# STM32C531xx register map
File version: 1.0
Registers are 32-bit, read-write, reset 0x0 unless marked. A register's access mark holds for its fields unless they carry their own. Offsets are from the block's base; [hi:lo] are bit positions; {n}, {i} and the like mark numbered series.

## PWR — Power Control (PWR)
Base 0x44020800
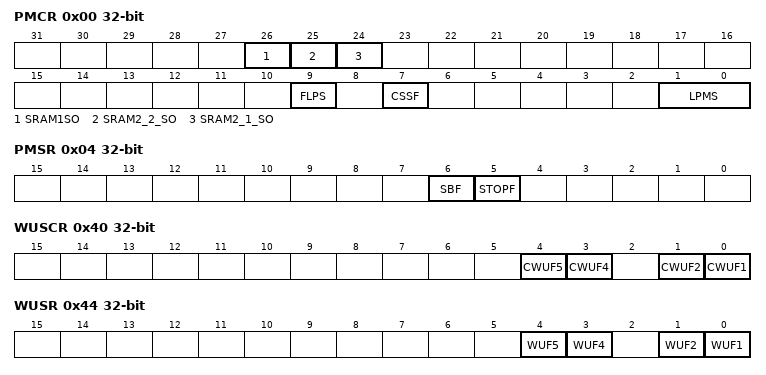
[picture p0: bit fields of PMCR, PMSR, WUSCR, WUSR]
0x00 PMCR — PWR power mode control register
  [26] SRAM1SO
  [25] SRAM2_2_SO
  [24] SRAM2_1_SO
  [9] FLPS
  [7] CSSF
  [1:0] LPMS — low-power mode selection
0x04 PMSR ro — PWR status register
  [6] SBF — System standby flag
  [5] STOPF — Stop flag
0x24 RTCCR — PWR RTC domain control register
  [0] DRTCP — Disable RTC domain write protection
0x34 VMCR — PWR voltage monitor control register
  [0] PVDE — PVD enable
0x3C VMSR ro — PWR voltage monitor status register
  [22] PVDO — programmable voltage detect output
0x40 WUSCR — PWR wake-up status clear register
  [4] CWUF5, [3] CWUF4, [1] CWUF2, [0] CWUF1
0x44 WUSR ro — PWR wake-up status register
  [4] WUF5 — wake-up pin WUFx flag
  [3] WUF4 — wake-up pin WUFx flag
  [1] WUF2 — wake-up pin WUFx flag
  [0] WUF1 — wake-up pin WUFx flag
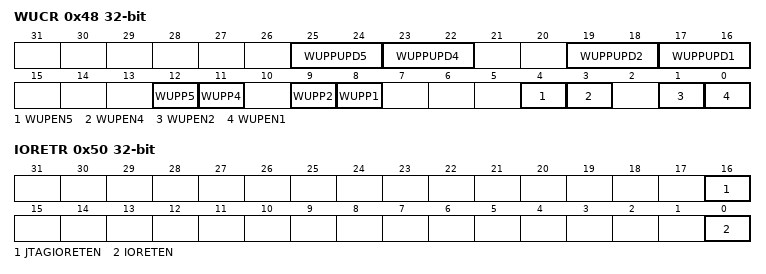
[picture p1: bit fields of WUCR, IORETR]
0x48 WUCR — PWR wake-up configuration register
  [25:24] WUPPUPD5
  [23:22] WUPPUPD4
  [19:18] WUPPUPD2
  [17:16] WUPPUPD1
  [12] WUPP5
  [11] WUPP4
  [9] WUPP2
  [8] WUPP1
  [4] WUPEN5 — Enable wake-up pin WKUPx (x = 7 to 1)
  [3] WUPEN4 — Enable wake-up pin WKUPx (x = 7 to 1)
  [1] WUPEN2 — Enable wake-up pin WKUPx (x = 7 to 1)
  [0] WUPEN1 — Enable wake-up pin WKUPx (x = 7 to 1)
0x50 IORETR — PWR I/O retention register
  [16] JTAGIORETEN — IO retention enable for JTAG I/Os
  [0] IORETEN — IO retention enable
0x104 PRIVCFGR — PWR privilege configuration register
  [1] PRIV

## EXTI — Extended interrupts and event controller (EXTI)
Base 0x44022000
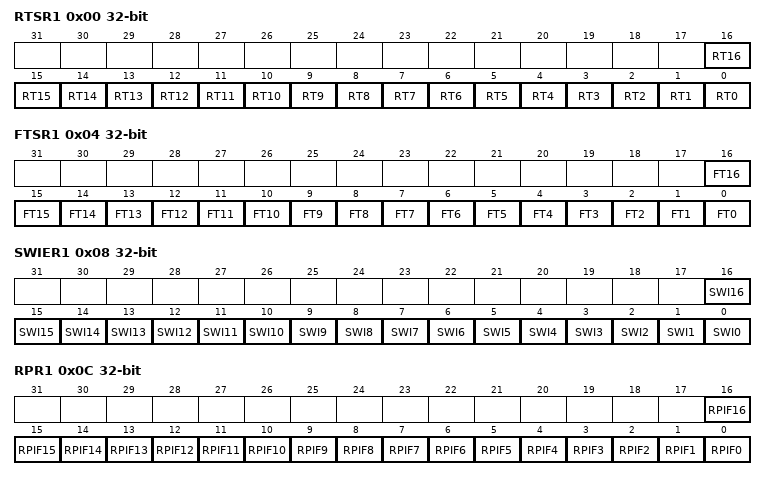
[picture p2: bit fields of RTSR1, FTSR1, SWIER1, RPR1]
0x00 RTSR1 — EXTI Rising Trigger Selection Register 1
  [n] RT{n} (n=0..16)
0x04 FTSR1 — EXTI Falling Trigger Selection Register 1
  [n] FT{n} (n=0..16)
0x08 SWIER1 — EXTI Software Interrupt event Register 1
  [n] SWI{n} (n=0..16) — Software interrupt on event {n}
0x0C RPR1 — EXTI Rising Pending Register 1
  [n] RPIF{n} (n=0..16)
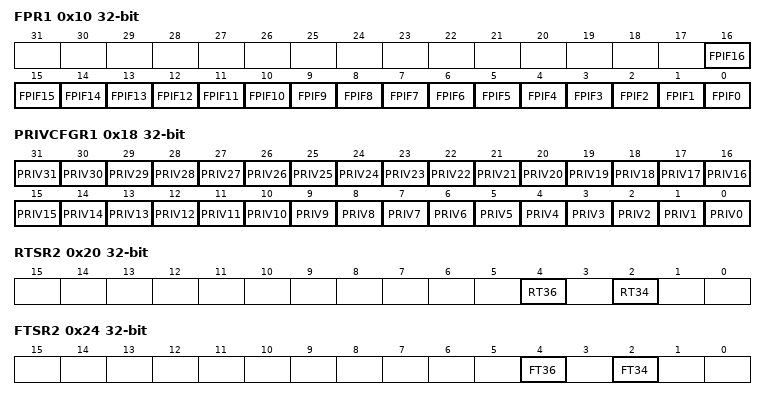
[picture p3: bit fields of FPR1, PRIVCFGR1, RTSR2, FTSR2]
0x10 FPR1 — EXTI Falling Pending Register 1
  [n] FPIF{n} (n=0..16)
0x18 PRIVCFGR1 — EXTI Privilege Configuration Register 1
  [n] PRIV{n} (n=0..31) — Privilege enable on event input {n}
0x20 RTSR2 — EXTI Rising Trigger Selection Register 2
  [4] RT36, [2] RT34
0x24 FTSR2 — EXTI Falling Trigger Selection Register 2
  [4] FT36, [2] FT34
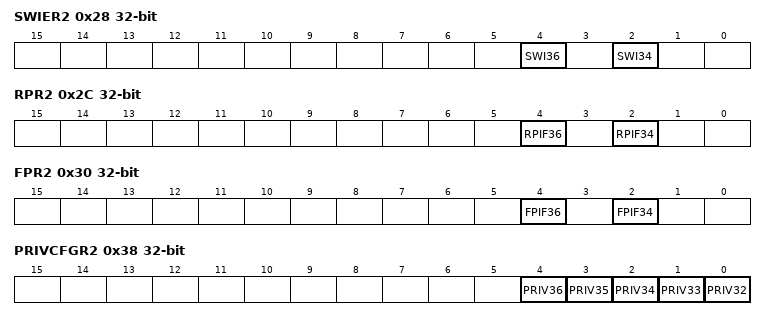
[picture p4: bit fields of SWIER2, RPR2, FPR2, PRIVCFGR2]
0x28 SWIER2 — EXTI Software Interrupt event Register 2
  [4] SWI36 — Software Interrupt on event 36
  [2] SWI34 — Software Interrupt on event 34
0x2C RPR2 — EXTI Rising Pending Register 2
  [4] RPIF36, [2] RPIF34
0x30 FPR2 — EXTI Falling Pending Register 2
  [4] FPIF36, [2] FPIF34
0x38 PRIVCFGR2 — EXTI Privilege Configuration Register 2
  [n-32] PRIV{n} (n=32..36) — Privilege enable on event input {n}
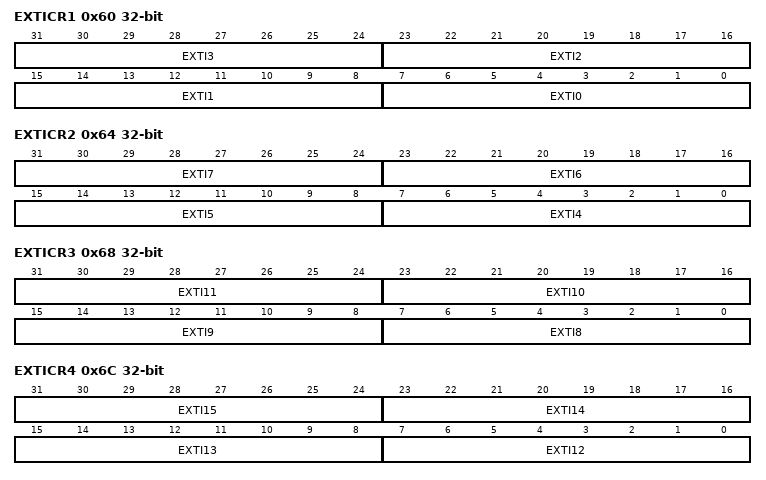
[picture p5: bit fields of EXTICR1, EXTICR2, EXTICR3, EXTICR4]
0x60 EXTICR1 — EXIT External Interrupt Configuration Register
  [8n+7:8n] EXTI{n} (n=0..3) — EXTI{n} GPIO port selection
0x64 EXTICR2 — EXIT External Interrupt Configuration Register
  [8n-25:8n-32] EXTI{n} (n=4..7) — EXTI{n} GPIO port selection
0x68 EXTICR3 — EXIT External Interrupt Configuration Register
  [8n-57:8n-64] EXTI{n} (n=8..11) — EXTI{n} GPIO port selection
0x6C EXTICR4 — EXIT External Interrupt Configuration Register
  [8n-89:8n-96] EXTI{n} (n=12..15) — EXTI{n} GPIO port selection
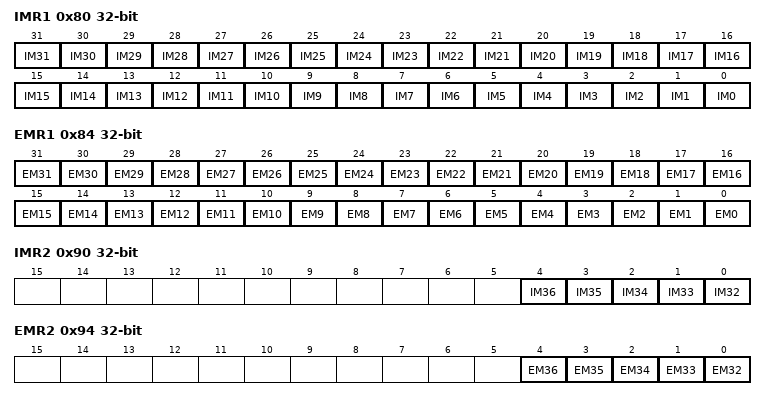
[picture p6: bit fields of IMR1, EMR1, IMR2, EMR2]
0x80 IMR1 — EXTI Interrupt Mask Register 1
  [n] IM{n} (n=0..31)
0x84 EMR1 — EXTI Event Mask Register 1
  [n] EM{n} (n=0..31)
0x90 IMR2 — EXTI Interrupt Mask Register 2
  [n-32] IM{n} (n=32..36)
0x94 EMR2 — EXTI Event Mask Register 2
  [n-32] EM{n} (n=32..36)

## DBGMCU — Debug MCU (DBGMCU)
Base 0x44024000
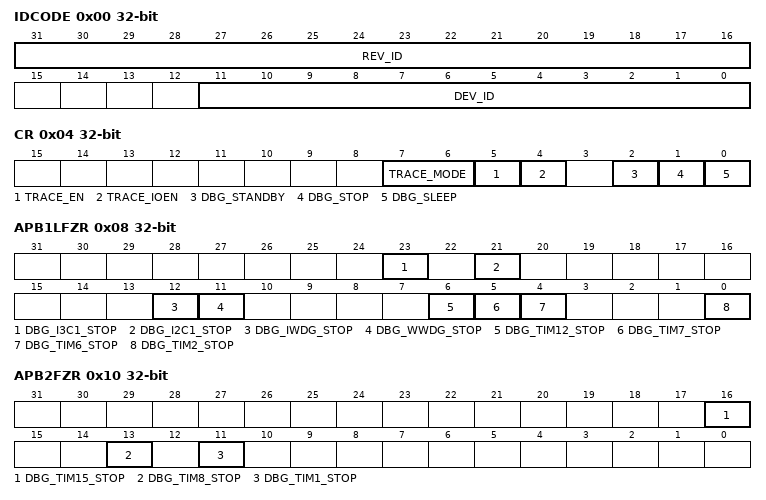
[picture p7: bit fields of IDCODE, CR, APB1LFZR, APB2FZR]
0x00 IDCODE ro — DBGMCU identity code register
  [31:16] REV_ID, [11:0] DEV_ID
0x04 CR — DBGMCU configuration register
  [7:6] TRACE_MODE, [5] TRACE_EN, [4] TRACE_IOEN, [2] DBG_STANDBY, [1] DBG_STOP, [0] DBG_SLEEP
0x08 APB1LFZR — DBGMCU APB1L peripheral freeze register
  [23] DBG_I3C1_STOP, [21] DBG_I2C1_STOP, [12] DBG_IWDG_STOP, [11] DBG_WWDG_STOP, [6] DBG_TIM12_STOP, [5] DBG_TIM7_STOP, [4] DBG_TIM6_STOP, [0] DBG_TIM2_STOP
0x10 APB2FZR — DBGMCU APB2 peripheral freeze register
  [16] DBG_TIM15_STOP, [13] DBG_TIM8_STOP, [11] DBG_TIM1_STOP
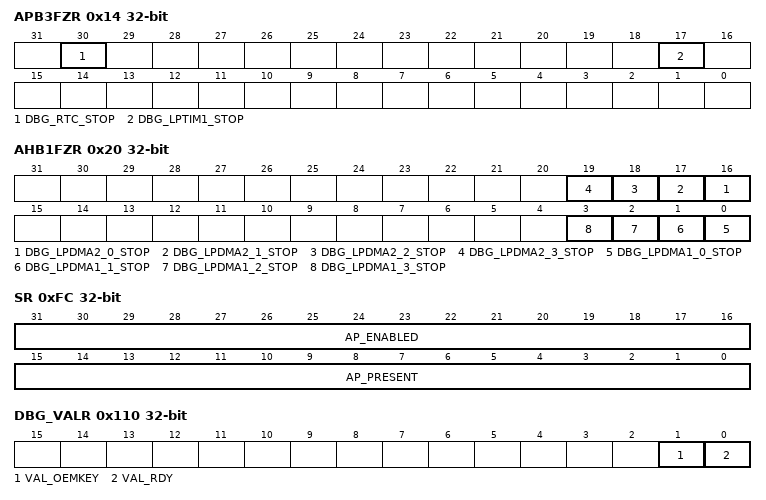
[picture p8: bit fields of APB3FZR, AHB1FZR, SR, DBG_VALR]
0x14 APB3FZR — DBGMCU APB3 peripheral freeze register
  [30] DBG_RTC_STOP, [17] DBG_LPTIM1_STOP
0x20 AHB1FZR — DBGMCU AHB1 peripheral freeze register
  [n+16] DBG_LPDMA2_{n}_STOP (n=0..3), [n] DBG_LPDMA1_{n}_STOP (n=0..3)
0xFC SR — DBGMCU status register
  [31:16] AP_ENABLED, [15:0] AP_PRESENT
0x100 DBG_AUTH_HOST — DBGMCU debug authentication mailbox host register
  [31:0] AUTH_KEY
0x104 DBG_AUTH_DEVICE ro — DBGMCU debug authentication mailbox device register
  [31:0] AUTH_ID
0x10C DBG_BSKEY_PWD — DBGMCU boundary-scan key password register
0x110 DBG_VALR ro — DBGMCU debug OEMKEY validation register
  [1] VAL_OEMKEY, [0] VAL_RDY
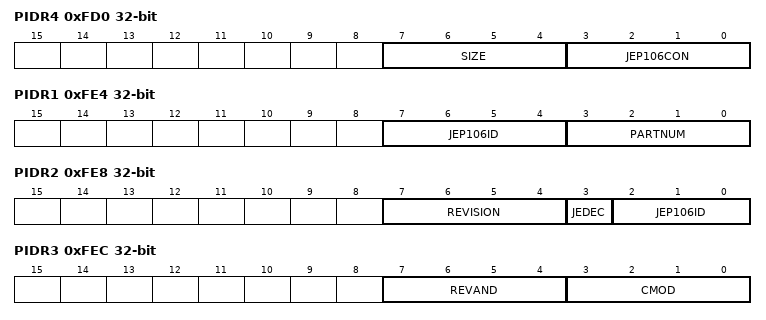
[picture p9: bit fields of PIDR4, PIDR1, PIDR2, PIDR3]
0xFD0 PIDR4 ro — DBGMCU CoreSight peripheral identity register 4
  [7:4] SIZE, [3:0] JEP106CON
0xFE0 PIDR0 ro — DBGMCU CoreSight peripheral identity register 0
  [7:0] PARTNUM
0xFE4 PIDR1 ro — DBGMCU CoreSight peripheral identity register 1
  [7:4] JEP106ID, [3:0] PARTNUM
0xFE8 PIDR2 ro — DBGMCU CoreSight peripheral identity register 2
  [7:4] REVISION, [3] JEDEC, [2:0] JEP106ID
0xFEC PIDR3 ro — DBGMCU CoreSight peripheral identity register 3
  [7:4] REVAND, [3:0] CMOD
0xFF0 CIDR0 ro — DBGMCU CoreSight component identity register 0
  [7:0] PREAMBLE
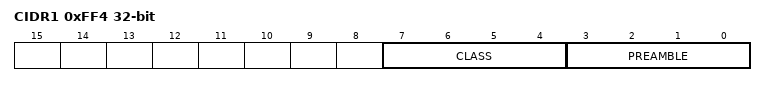
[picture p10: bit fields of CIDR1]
0xFF4 CIDR1 ro — DBGMCU CoreSight component identity register 1
  [7:4] CLASS, [3:0] PREAMBLE
0xFF8 CIDR2 ro — DBGMCU CoreSight component identity register 2
  [7:0] PREAMBLE
0xFFC CIDR3 ro — DBGMCU CoreSight component identity register 3
  [7:0] PREAMBLE
